# S1C31D01 register map
Vendor: Epson; Series: S1C31D01; File version: 1.00
CPU: CM0PLUS r0p1, little endian, MPU, no FPU, VTOR, 2 interrupt priority bits
Registers are 16-bit, read-write, reset 0x0 unless marked. A register's access mark holds for its fields unless they carry their own. Offsets are from the block's base; [hi:lo] are bit positions; {n}, {i} and the like mark numbered series; 'fields as' and 'values as' point back to an identical list.

## SPIA_0 — Synchronous serial interface control
Base 0x400003B0
Same registers: SPIA_1 0x40000670
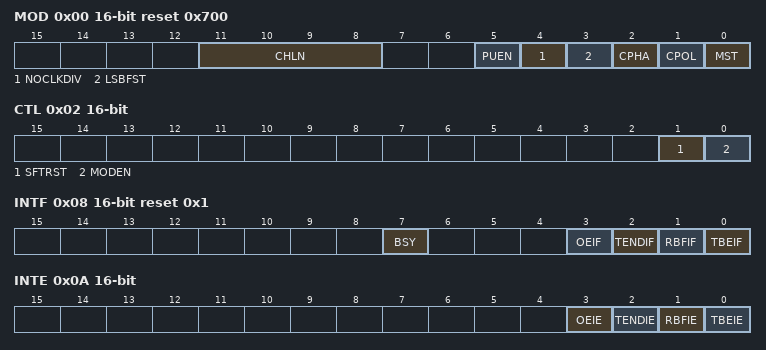
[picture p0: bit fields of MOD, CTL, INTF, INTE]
0x00 MOD reset 0x700 — Mode Register
  [11:8] CHLN — Data length select
    {v}={v+1}_BITS (v=1..15)
  [5] PUEN — #SPISS, SPICLK (input), SDI pull-up, pull-down enable
    0=DISABLE (Disable pull-up/down); 1=ENABLE (Enable pull-up/down)
  [4] NOCLKDIV — No USE T16 underflow pulse
    0=USE_T16; 1=NO_USE_T16
  [3] LSBFST — LSB first mode select
    0=MSB_FIRST; 1=LSB_FIRST (SB first)
  [2] CPHA — Clock phase select
  [1] CPOL — Clock polarity select
  [0] MST — Master mode select
    0=SLAVE (Slave mode); 1=MASTER (Master mode)
0x02 CTL — Control Register
  [1] SFTRST write-1-sets — Soft reset
    on write: 0=NON (No effect); 1=RESET (Issue software reset) | on read: 0=STOPPED (Software reset has finished (During normal operation)); 1=RUNNING (Software reset is executing)
  [0] MODEN — SPI enable
    0=DISABLE (Disable SPIA operations (In master mode, the operating clock is stopped)); 1=ENABLE (Enable SPIA operations (In master mode, the operating clock is supplied))
0x04 TXD — Transmit Data Register
  [15:0] TXD — Transmit buffer
0x06 RXD ro — Receive Data Register
  [15:0] RXD — Receive buffer
0x08 INTF reset 0x1 — Interrupt Flag Register
  [7] BSY ro — Transfer Busy / Slave Selected
    0=IDLE; 1=BUSY (Transmit/receive busy (master mode), #SPISSn = Low level (slave mode))
  [3] OEIF ro write-1-clears — Receive over write error flag
    0=NOT_OCCURED (No cause of interrupt occurred); 1=OCCURED (Cause of interrupt occurred)
  [2] TENDIF ro write-1-clears — Transfer End interrupt flag
    values as OEIF
  [1] RBFIF ro — Receive buffer full interrupt flag
    values as OEIF
  [0] TBEIF ro — Transmit buffer empty interrupt flag
    values as OEIF
0x0A INTE — Interrupt Enable Register
  [all] fields
    0=DISABLE; 1=ENABLE
  [3] OEIE — Receive over write error interrupt enable
  [2] TENDIE — Transfer end interrupt enable
  [1] RBFIE — Receive buffer full interrupt enable
  [0] TBEIE — Transmit buffer empty interrupt enable
0x0C TBEDMAEN — TBE DMA Enable Register
  [3:0] TBEDMAEN — TBE DMA request enable
0x0E RBFDMAEN — RBF DMA Enable Register
  [3:0] RBFDMAEN — RBF DMA request enable
    0=DISABLE; 1=ENABLE

## SNDA — SNDA Sound generatior
Base 0x40000700
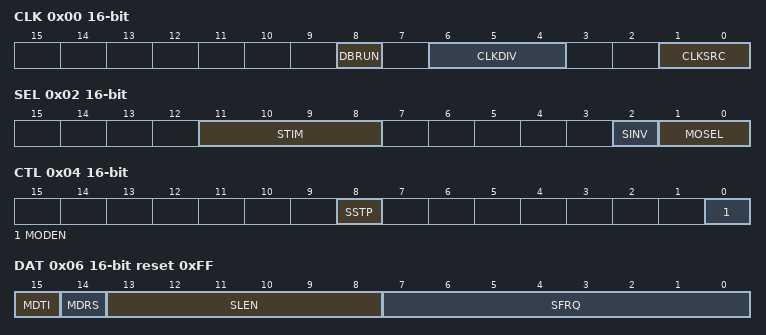
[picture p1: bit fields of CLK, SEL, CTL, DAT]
0x00 CLK — Clock Control Register
  [8] DBRUN — Enable clock on debug mode
    0=DISABLE; 1=ENABLE
  [6:4] CLKDIV — Clock division select
  [1:0] CLKSRC — Clock source select
    0=IOSC; 1=OSC1; 2=OSC3; 3=EXOSC
0x02 SEL — SND Selection Register
  [11:8] STIM — These bits select a tempo (when melody mode is selected) or a one-shot buzzer output duration (when one-shot buzzer mode is selected)
  [2] SINV — Enable clock on debug mode
    0=DIRECT (Direct Drive mode); 1=NORMAL (Normal Drive mode)
  [1:0] MOSEL — These bits select a sound output mode
0x04 CTL — SND Control Register
  [8] SSTP — Sound Stop control
  [0] MODEN — This bit enables the SNDA operations
    0=DISABLE ((The operating clock is stopped); 1=ENABLE (The operating clock is supplied)
0x06 DAT reset 0xFF — SND Data Register
  [15] MDTI — Melody Tie Symbol
  [14] MDRS — Melody Reset Symbol
  [13:8] SLEN — Melody Note Symbol
  [7:0] SFRQ — Melody Frequency/Buzzer Frequency
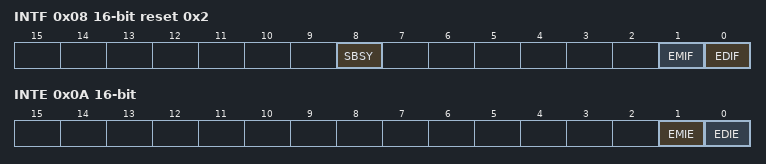
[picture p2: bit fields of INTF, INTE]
0x08 INTF reset 0x2 — SND Interrupt Flag Register
  [8] SBSY ro — Sound Busy Status
  [1] EMIF ro write-1-clears — Empty Interrupt Flag
    0=NOT_OCCURED (No cause of interrupt occurred); 1=OCCURED (Cause of interrupt occurred)
  [0] EDIF write-1-clears — END interrupt Flag
    values as EMIF
0x0A INTE — SND Interrupt Flag Register
  [1] EMIE — Empty Interrupt Enable
    0=DISABLE (Interrupt Disable); 1=ENABLE (Interrupt Enable)
  [0] EDIE — END interrupt Enable
    0=DISABLE (Interrupt Disable); 1=ENABLE (Interrupt Enable)
0x0C EMDMAEN — Sound Buffer Empty DMA Request Enable Register
  [3:0] EMDMAEN — These bits enable the SNDA to issue a DMA transfer request to the corresponding DMA controllerchannel when a sound buffer empty state has occurred.
